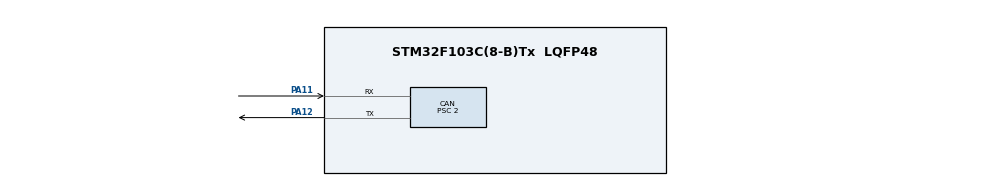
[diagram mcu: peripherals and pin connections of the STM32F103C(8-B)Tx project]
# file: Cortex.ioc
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CAN.ABOM=ENABLE
CAN.BS1=CAN_BS1_13TQ
CAN.BS2=CAN_BS2_2TQ
CAN.CalculateTimeBit=4000
CAN.CalculateTimeQuantum=250.0
CAN.Prescaler=2
FREERTOS.Tasks01=CAN_task,0,128,can_task,Default,NULL,Dynamic,NULL,NULL
Mcu.Family=STM32F1
Mcu.Name=STM32F103C(8-B)Tx
Mcu.Package=LQFP48
NVIC.PriorityGroup=NVIC_PRIORITYGROUP_4
NVIC.TIM1_UP_IRQn=true\:0\:0\:false\:false\:true\:false\:false
NVIC.TimeBase=TIM1_UP_IRQn
NVIC.TimeBaseIP=TIM1
PA11.Mode=Master
PA11.Signal=CAN_RX
PA12.Mode=Master
PA12.Signal=CAN_TX
PA13.Mode=JTAG_4_pins
PA13.Signal=SYS_JTMS-SWDIO
PA14.Mode=JTAG_4_pins
PA14.Signal=SYS_JTCK-SWCLK
PA15.Mode=JTAG_4_pins
PA15.Signal=SYS_JTDI
PB3.Mode=JTAG_4_pins
PB3.Signal=SYS_JTDO-TRACESWO
ProjectManager.HeapSize=0x200
ProjectManager.StackSize=0x400
ProjectManager.TargetToolchain=EWARM
RCC.APB1Freq_Value=8000000
RCC.APB2Freq_Value=8000000
VP_FREERTOS_VS_ENABLE.Mode=Enabled
VP_SYS_VS_tim1.Mode=TIM1
VP_TIM2_VS_ClockSourceINT.Mode=Internal
VP_TIM2_VS_ClockSourceITR.Mode=TriggerSource_ITR0
VP_TIM2_VS_ControllerModeTrigger.Mode=Trigger Mode
board=Cortex

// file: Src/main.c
/**
  ******************************************************************************
  * File Name          : main.c
  * Description        : Main program body
  ******************************************************************************
  * This notice applies to any and all portions of this file
  * that are not between comment pairs USER CODE BEGIN and
  * USER CODE END. Other portions of this file, whether
  * inserted by the user or by software development tools
  * are owned by their respective copyright owners.
  *
  * Copyright (c) 2017 STMicroelectronics International N.V.
  * All rights reserved.
  *
  * Redistribution and use in source and binary forms, with or without
  * modification, are permitted, provided that the following conditions are met:
  *
  * 1. Redistribution of source code must retain the above copyright notice,
  *    this list of conditions and the following disclaimer.
  * 2. Redistributions in binary form must reproduce the above copyright notice,
  *    this list of conditions and the following disclaimer in the documentation
  *    and/or other materials provided with the distribution.
  * 3. Neither the name of STMicroelectronics nor the names of other
  *    contributors to this software may be used to endorse or promote products
  *    derived from this software without specific written permission.
  * 4. This software, including modifications and/or derivative works of this
  *    software, must execute solely and exclusively on microcontroller or
  *    microprocessor devices manufactured by or for STMicroelectronics.
  * 5. Redistribution and use of this software other than as permitted under
  *    this license is void and will automatically terminate your rights under
  *    this license.
  *
  * THIS SOFTWARE IS PROVIDED BY STMICROELECTRONICS AND CONTRIBUTORS "AS IS"
  * AND ANY EXPRESS, IMPLIED OR STATUTORY WARRANTIES, INCLUDING, BUT NOT
  * LIMITED TO, THE IMPLIED WARRANTIES OF MERCHANTABILITY, FITNESS FOR A
  * PARTICULAR PURPOSE AND NON-INFRINGEMENT OF THIRD PARTY INTELLECTUAL PROPERTY
  * RIGHTS ARE DISCLAIMED TO THE FULLEST EXTENT PERMITTED BY LAW. IN NO EVENT
  * SHALL STMICROELECTRONICS OR CONTRIBUTORS BE LIABLE FOR ANY DIRECT, INDIRECT,
  * INCIDENTAL, SPECIAL, EXEMPLARY, OR CONSEQUENTIAL DAMAGES (INCLUDING, BUT NOT
  * LIMITED TO, PROCUREMENT OF SUBSTITUTE GOODS OR SERVICES; LOSS OF USE, DATA,
  * OR PROFITS; OR BUSINESS INTERRUPTION) HOWEVER CAUSED AND ON ANY THEORY OF
  * LIABILITY, WHETHER IN CONTRACT, STRICT LIABILITY, OR TORT (INCLUDING
  * NEGLIGENCE OR OTHERWISE) ARISING IN ANY WAY OUT OF THE USE OF THIS SOFTWARE,
  * EVEN IF ADVISED OF THE POSSIBILITY OF SUCH DAMAGE.
  *
  ******************************************************************************
  */
#include "main.h"
#include "stm32f1xx_hal.h"
#include "cmsis_os.h"

/* USER CODE BEGIN Includes */
#include "can_settings.h"
/* USER CODE END Includes */

CAN_HandleTypeDef hcan;

TIM_HandleTypeDef htim2;

osThreadId CAN_taskHandle;

/* USER CODE BEGIN PV */
/* Private variables ---------------------------------------------------------*/

/* USER CODE END PV */

void SystemClock_Config(void);
static void MX_GPIO_Init(void);
static void MX_CAN_Init(void);
static void MX_TIM2_Init(void);
void can_task(void const * argument);

/* USER CODE BEGIN PFP */
/* Private function prototypes -----------------------------------------------*/

/* USER CODE END PFP */

int main(void)
{

  /* MCU Configuration----------------------------------------------------------*/

  /* Reset of all peripherals, Initializes the Flash interface and the Systick. */
  HAL_Init();

  /* Configure the system clock */
  SystemClock_Config();

  /* Initialize all configured peripherals */
  MX_GPIO_Init();
  MX_CAN_Init();
  MX_TIM2_Init();

  /* Create the thread(s) */
  /* definition and creation of CAN_task */
  osThreadDef(CAN_task, can_task, osPriorityNormal, 0, 128);
  CAN_taskHandle = osThreadCreate(osThread(CAN_task), NULL);

  /* Start scheduler */
  osKernelStart();

  /* We should never get here as control is now taken by the scheduler */

  /* Infinite loop */
  while (1)
  {

  }

}

/** System Clock Configuration
*/
void SystemClock_Config(void)
{

  RCC_OscInitTypeDef RCC_OscInitStruct;
  RCC_ClkInitTypeDef RCC_ClkInitStruct;

    /**Initializes the CPU, AHB and APB busses clocks
    */
  RCC_OscInitStruct.OscillatorType = RCC_OSCILLATORTYPE_HSI;
  RCC_OscInitStruct.HSIState = RCC_HSI_ON;
  RCC_OscInitStruct.HSICalibrationValue = 16;
  RCC_OscInitStruct.PLL.PLLState = RCC_PLL_NONE;
  if (HAL_RCC_OscConfig(&RCC_OscInitStruct) != HAL_OK)
  {
    _Error_Handler(__FILE__, __LINE__);
  }

    /**Initializes the CPU, AHB and APB busses clocks
    */
  RCC_ClkInitStruct.ClockType = RCC_CLOCKTYPE_HCLK|RCC_CLOCKTYPE_SYSCLK
                              |RCC_CLOCKTYPE_PCLK1|RCC_CLOCKTYPE_PCLK2;
  RCC_ClkInitStruct.SYSCLKSource = RCC_SYSCLKSOURCE_HSI;
  RCC_ClkInitStruct.AHBCLKDivider = RCC_SYSCLK_DIV1;
  RCC_ClkInitStruct.APB1CLKDivider = RCC_HCLK_DIV1;
  RCC_ClkInitStruct.APB2CLKDivider = RCC_HCLK_DIV1;

  if (HAL_RCC_ClockConfig(&RCC_ClkInitStruct, FLASH_LATENCY_0) != HAL_OK)
  {
    _Error_Handler(__FILE__, __LINE__);
  }

    /**Configure the Systick interrupt time
    */
  HAL_SYSTICK_Config(HAL_RCC_GetHCLKFreq()/1000);

    /**Configure the Systick
    */
  HAL_SYSTICK_CLKSourceConfig(SYSTICK_CLKSOURCE_HCLK);

  /* SysTick_IRQn interrupt configuration */
  HAL_NVIC_SetPriority(SysTick_IRQn, 15, 0);
}

/* CAN init function */
static void MX_CAN_Init(void)
{

  hcan.Instance = CAN1;
  hcan.Init.Prescaler = 2;
  hcan.Init.Mode = CAN_MODE_NORMAL;
  hcan.Init.SJW = CAN_SJW_1TQ;
  hcan.Init.BS1 = CAN_BS1_13TQ;
  hcan.Init.BS2 = CAN_BS2_2TQ;
  hcan.Init.TTCM = DISABLE;
  hcan.Init.ABOM = ENABLE;
  hcan.Init.AWUM = DISABLE;
  hcan.Init.NART = DISABLE;
  hcan.Init.RFLM = DISABLE;
  hcan.Init.TXFP = DISABLE;
  if (HAL_CAN_Init(&hcan) != HAL_OK)
  {
    _Error_Handler(__FILE__, __LINE__);
  }

}

/* TIM2 init function */
static void MX_TIM2_Init(void)
{

  TIM_ClockConfigTypeDef sClockSourceConfig;
  TIM_SlaveConfigTypeDef sSlaveConfig;
  TIM_MasterConfigTypeDef sMasterConfig;

  htim2.Instance = TIM2;
  htim2.Init.Prescaler = 0;
  htim2.Init.CounterMode = TIM_COUNTERMODE_UP;
  htim2.Init.Period = 0;
  htim2.Init.ClockDivision = TIM_CLOCKDIVISION_DIV1;
  htim2.Init.AutoReloadPreload = TIM_AUTORELOAD_PRELOAD_DISABLE;
  if (HAL_TIM_Base_Init(&htim2) != HAL_OK)
  {
    _Error_Handler(__FILE__, __LINE__);
  }

  sClockSourceConfig.ClockSource = TIM_CLOCKSOURCE_INTERNAL;
  if (HAL_TIM_ConfigClockSource(&htim2, &sClockSourceConfig) != HAL_OK)
  {
    _Error_Handler(__FILE__, __LINE__);
  }

  sSlaveConfig.SlaveMode = TIM_SLAVEMODE_TRIGGER;
  sSlaveConfig.InputTrigger = TIM_TS_ITR0;
  if (HAL_TIM_SlaveConfigSynchronization(&htim2, &sSlaveConfig) != HAL_OK)
  {
    _Error_Handler(__FILE__, __LINE__);
  }

  sMasterConfig.MasterOutputTrigger = TIM_TRGO_RESET;
  sMasterConfig.MasterSlaveMode = TIM_MASTERSLAVEMODE_DISABLE;
  if (HAL_TIMEx_MasterConfigSynchronization(&htim2, &sMasterConfig) != HAL_OK)
  {
    _Error_Handler(__FILE__, __LINE__);
  }

}

/** Configure pins as
        * Analog
        * Input
        * Output
        * EVENT_OUT
        * EXTI
*/
static void MX_GPIO_Init(void)
{

  /* GPIO Ports Clock Enable */
  __HAL_RCC_GPIOA_CLK_ENABLE();
  __HAL_RCC_GPIOB_CLK_ENABLE();

}

/* USER CODE BEGIN 4 */
CanTxMsgTypeDef message;
/* USER CODE END 4 */

/* can_task function */
void can_task(void const * argument)
{

  /* USER CODE BEGIN 5 */
  /* Infinite loop */
  for(;;)
  {
    message.Data[0] = 0x11;
    message.Data[1] = 0x22;
    message.Data[2] = 0x33;
    message.Data[3] = 0x44;
    message.Data[4] = 0x55;
    message.Data[5] = 0x66;
    message.Data[6] = 0x77;
    message.Data[7] = 0x88;

    message.IDE = CAN_ID_STD;
    message.StdId = 0x10;

    hcan.pTxMsg = &message;

    HAL_CAN_Transmit(&hcan, 5);
    osDelay(100);
  }
  /* USER CODE END 5 */
}

void HAL_TIM_PeriodElapsedCallback(TIM_HandleTypeDef *htim)
{
  if (htim->Instance == TIM1) {
    HAL_IncTick();
  }
}

void _Error_Handler(char * file, int line)
{
  while(1)
  {
  }
}

/************************ (C) COPYRIGHT STMicroelectronics *****END OF FILE****/
